# AVR16LA28 register map
Vendor: Atmel; File version: 1.0
CPU: other r0p0, little endian, no MPU, no FPU, 4 interrupt priority bits
Registers are 8-bit, read-write, reset 0x0 unless marked. A register's access mark holds for its fields unless they carry their own. Offsets are from the block's base; [hi:lo] are bit positions; {n}, {i} and the like mark numbered series; <NAME> marks a mode.

## ADC0 — Analog to Digital Converter
Base 0x00800600
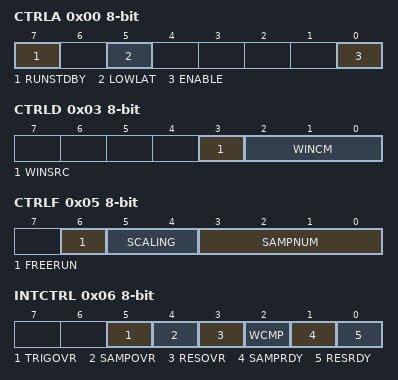
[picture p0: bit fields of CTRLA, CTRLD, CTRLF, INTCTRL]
0x00 CTRLA — Control A
  [7] RUNSTDBY — Run in Standby Mode
  [5] LOWLAT — Low Latency
  [0] ENABLE — ADC Enable
0x01 CTRLB — Control B
  [4:0] PRESC — ADC Prescaler
    {v}=DIV{v+2} (CLK_PER divided by {v+2}) (v=0..30)
0x02 CTRLC — Control C
  [2:0] REFSEL — Reference Selection
    0=VDD; 2=EXTVREF (External reference from EXTVREF0 pin); 3=0V512 (Internal reference 0.512 V); 4=1V024 (Internal reference 1.024 V); 5=2V048 (Internal reference 2.048 V); 6=4V096 (Internal reference 4.096 V); 7=2V500 (Internal reference 2.500 V)
0x03 CTRLD — Control D
  [3] WINSRC — Window Mode Source
    0=RESULT (Use RESULT[15:0] as Window Comparator Source); 1=SAMPLE (Use SAMPLE[15:0] as Window Comparator source)
  [2:0] WINCM — Window Comparator Mode
    0=NONE (No Window Comparison); 1=BELOW (OUTPUT < WINLT); 2=ABOVE (OUTPUT > WINHT); 3=INSIDE (WINLT < OUTPUT < WINHT); 4=OUTSIDE (OUTPUT < WINLT or OUTPUT >WINHT)
0x04 CTRLE — Control E
  [7:0] SAMPDUR — Sample Duration
0x05 CTRLF — Control F
  [6] FREERUN — Free Running
  [5:4] SCALING — Result Scaling
    0=NORMAL (ADC output of sample or accumulated result is right adjusted. If accumulating more then 64 samples, result is left adjusted); 1=LEFTADJ (ADC output is left adjusted); 2=AVERAGE (Accumulated ADC result is averaged and right adjusted)
  [3:0] SAMPNUM — Sample Accumulation Number Select
    0=NONE (No accumulation, single sample per conversion result); 1=ACC2 (2 samples accumulated); 2=ACC4 (4 samples accumulated); 3=ACC8 (8 samples accumulated); 4=ACC16 (16 samples accumulated); 5=ACC32 (32 samples accumulated); 6=ACC64 (64 samples accumulated); 7=ACC128 (128 samples accumulated); 8=ACC256 (256 samples accumulated); 9=ACC512 (512 samples accumulated); 10=ACC1024 (1024 samples accumulated)
0x06 INTCTRL — Interrupt Control
  [5] TRIGOVR — Trigger Overrun Interrupt Enable
  [4] SAMPOVR — Sample Overwrite Interrupt Enable
  [3] RESOVR — Result Overwrite Interrupt Enable
  [2] WCMP — Window Comparator Interrupt Enable
  [1] SAMPRDY — Sample Ready Interrupt Enable
  [0] RESRDY — Result Ready Interrupt Enable
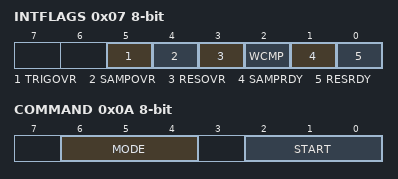
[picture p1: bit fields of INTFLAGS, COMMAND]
0x07 INTFLAGS — Interrupt Flags
  [5] TRIGOVR — Trigger Overrun Interrupt Flag
  [4] SAMPOVR — Sample Overwrite Interrupt Flag
  [3] RESOVR — Result Overwrite Interrupt Flag
  [2] WCMP — Window Comparator Interrupt Flag
  [1] SAMPRDY — Sample Ready Interrupt Flag
  [0] RESRDY — Result Ready Interrupt Flag
0x08 STATUS ro
  [0] ADCBUSY
0x09 DBGCTRL — Debug Control
  [0] DBGRUN — Run in Debug Mode
0x0A COMMAND
  [6:4] MODE
    0=SINGLE_8BIT (Single Conversion with 8-bit resolution); 1=SINGLE_10BIT (Single Conversion with 10-bit resolution); 2=SERIES (Series with accumulation, separate trigger for every 10-bit conversion); 3=BURST (Burst with accumulation, one trigger will run SAMPNUM 10-bit conversions in one sequence); 7=ACCTEST (Accumulator diagnostic mode)
  [2:0] START — Start Conversion
    0=STOP (Stop an ongoing conversion); 1=IMMEDIATE (Start a conversion immediately. This will be set back to STOP when the first conversion is done, unless Free-Running mode is enabled); 2=MUXPOS (Start when a write to the MUXPOS register is done); 4=EVENT (Start when an event is received by the ADC)
0x0B MUXPOS — Positive Input Multiplexer
  [6:0] MUXPOS
    {v}=AIN{v} (ADC input pin {v}) (v=0..7); 16=AIN16 (ADC input pin 16); 17=AIN17 (ADC input pin 17); {v}=AIN{v} (ADC input pin {v}) (v=22..27); 41=TEMPSENSE (Temperature Sensor); 42=VDDDIV10 (VDD Divided by 10); 43=AC0REFSCALE (AC0 Reference Scaler); 62=PTC (Peripheral Touch Controller)
0x0C RESULT 16-bit (reset mask 0xFF)
  [15:0] RESULT ro — ADC Result
0x0E SAMPLE 16-bit (reset mask 0xFF)
  [15:0] SAMPLE ro — ADC Sample
0x10 WINLT 16-bit (reset mask 0xFF) — Window Low Threshold
0x12 WINHT 16-bit (reset mask 0xFF) — Window High Threshold
0x14 TEMP — Temporary
